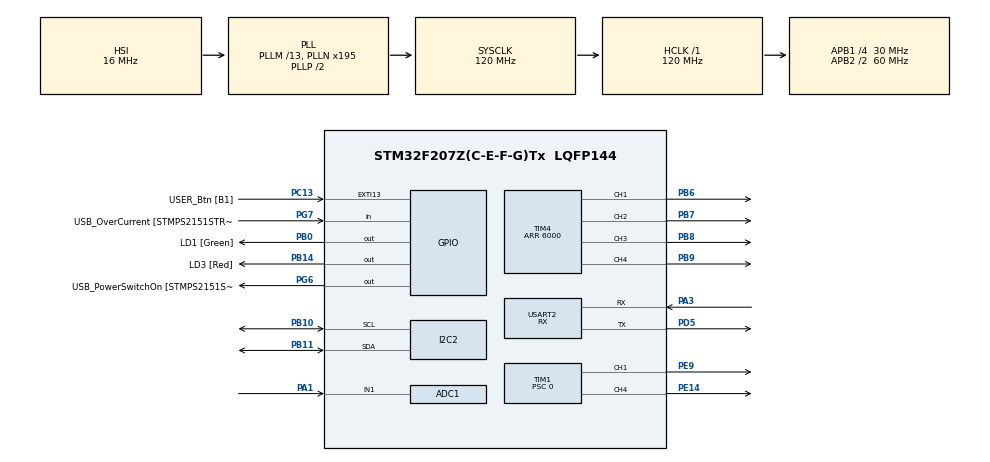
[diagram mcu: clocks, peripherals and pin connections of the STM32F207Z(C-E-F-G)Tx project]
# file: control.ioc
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ADC1.Channel-2\#ChannelRegularConversion=ADC_CHANNEL_1
ADC1.NbrOfConversionFlag=1
ADC1.Rank-2\#ChannelRegularConversion=1
ADC1.SamplingTime-2\#ChannelRegularConversion=ADC_SAMPLETIME_3CYCLES
ADC1.master=1
Dma.Request0=TIM1_CH1
Dma.Request1=TIM1_CH4/TRIG/COM
Dma.TIM1_CH1.0.Direction=DMA_MEMORY_TO_PERIPH
Dma.TIM1_CH1.0.FIFOMode=DMA_FIFOMODE_DISABLE
Dma.TIM1_CH1.0.Instance=DMA2_Stream1
Dma.TIM1_CH1.0.MemDataAlignment=DMA_MDATAALIGN_HALFWORD
Dma.TIM1_CH1.0.MemInc=DMA_MINC_ENABLE
Dma.TIM1_CH1.0.Mode=DMA_CIRCULAR
Dma.TIM1_CH1.0.PeriphDataAlignment=DMA_PDATAALIGN_HALFWORD
Dma.TIM1_CH1.0.PeriphInc=DMA_PINC_DISABLE
Dma.TIM1_CH1.0.Priority=DMA_PRIORITY_HIGH
Dma.TIM1_CH4/TRIG/COM.1.Direction=DMA_MEMORY_TO_PERIPH
Dma.TIM1_CH4/TRIG/COM.1.FIFOMode=DMA_FIFOMODE_DISABLE
Dma.TIM1_CH4/TRIG/COM.1.Instance=DMA2_Stream4
Dma.TIM1_CH4/TRIG/COM.1.MemDataAlignment=DMA_MDATAALIGN_HALFWORD
Dma.TIM1_CH4/TRIG/COM.1.MemInc=DMA_MINC_ENABLE
Dma.TIM1_CH4/TRIG/COM.1.Mode=DMA_CIRCULAR
Dma.TIM1_CH4/TRIG/COM.1.PeriphDataAlignment=DMA_PDATAALIGN_HALFWORD
Dma.TIM1_CH4/TRIG/COM.1.PeriphInc=DMA_PINC_DISABLE
Dma.TIM1_CH4/TRIG/COM.1.Priority=DMA_PRIORITY_HIGH
I2C2.DualAddressMode=I2C_DUALADDRESS_DISABLE
I2C2.I2C_Mode=I2C_Standard
I2C2.OwnAddress=0x53
Mcu.Family=STM32F2
Mcu.Name=STM32F207Z(C-E-F-G)Tx
Mcu.Package=LQFP144
NVIC.DMA2_Stream1_IRQn=true\:0\:0\:false\:false\:true\:false\:true\:true
NVIC.DMA2_Stream4_IRQn=true\:0\:0\:false\:false\:true\:false\:true\:true
NVIC.I2C2_EV_IRQn=true\:0\:0\:false\:false\:true\:true\:true\:true
NVIC.PriorityGroup=NVIC_PRIORITYGROUP_4
NVIC.USART2_IRQn=true\:0\:0\:false\:false\:true\:true\:true\:true
PA1.Signal=ADCx_IN1
PA10.GPIO_Label=USB_ID
PA10.Signal=USB_OTG_FS_ID
PA12.GPIO_Label=USB_DP
PA12.Signal=USB_OTG_FS_DP
PA13.GPIO_Label=TMS
PA13.Mode=Serial_Wire
PA13.Signal=SYS_JTMS-SWDIO
PA14.GPIO_Label=TCK
PA14.Mode=Serial_Wire
PA14.Signal=SYS_JTCK-SWCLK
PA2.GPIO_Label=RMII_MDIO [LAN8742A-CZ-TR_MDIO]
PA2.Signal=ETH_MDIO
PA3.Mode=Asynchronous
PA3.Signal=USART2_RX
PA7.GPIO_Label=RMII_CRS_DV [LAN8742A-CZ-TR_CRS_DV]
PA7.Signal=ETH_CRS_DV
PA9.GPIO_Label=USB_VBUS
PA9.Signal=USB_OTG_FS_VBUS
PB0.GPIO_Label=LD1 [Green]
PB0.Signal=GPIO_Output
PB10.Mode=I2C
PB10.Signal=I2C2_SCL
PB11.Mode=I2C
PB11.Signal=I2C2_SDA
PB13.GPIO_Label=RMII_TXD1 [LAN8742A-CZ-TR_TXD1]
PB13.Signal=ETH_TXD1
PB14.GPIO_Label=LD3 [Red]
PB14.Signal=GPIO_Output
PB3.GPIO_Label=SWO
PB3.Signal=SYS_JTDO-SWO
PB6.Signal=S_TIM4_CH1
PB7.Signal=S_TIM4_CH2
PB8.Signal=S_TIM4_CH3
PB9.Signal=S_TIM4_CH4
PC1.GPIO_Label=RMII_MDC [LAN8742A-CZ-TR_MDC]
PC1.Signal=ETH_MDC
PC13.GPIO_Label=USER_Btn [B1]
PC13.Signal=GPXTI13
PC14-OSC32_IN.Mode=LSE-External-Oscillator
PC14-OSC32_IN.Signal=RCC_OSC32_IN
PC15-OSC32_OUT.Mode=LSE-External-Oscillator
PC15-OSC32_OUT.Signal=RCC_OSC32_OUT
PC4.GPIO_Label=RMII_RXD0 [LAN8742A-CZ-TR_RXD0]
PC4.Signal=ETH_RXD0
PC5.GPIO_Label=RMII_RXD1 [LAN8742A-CZ-TR_RXD1]
PC5.Signal=ETH_RXD1
PD5.Mode=Asynchronous
PD5.Signal=USART2_TX
PD8.GPIO_Label=STLK_RX [STM32F103CBT6_PA2]
PD8.Signal=USART3_TX
PD9.GPIO_Label=STLK_TX [STM32F103CBT6_PA3]
PD9.Signal=USART3_RX
PE14.Signal=S_TIM1_CH4
PE9.Signal=S_TIM1_CH1
PG11.GPIO_Label=RMII_TX_EN [LAN8742A-CZ-TR_TXEN]
PG11.Signal=ETH_TX_EN
PG13.GPIO_Label=RMII_TXD0 [LAN8742A-CZ-TR_TXD0]
PG13.Signal=ETH_TXD0
PG6.GPIO_Label=USB_PowerSwitchOn [STMPS2151STR_EN]
PG6.Signal=GPIO_Output
PG7.GPIO_Label=USB_OverCurrent [STMPS2151STR_FAULT]
PG7.Signal=GPIO_Input
PH0-OSC_IN.GPIO_Label=MCO [STM32F103CBT6_PA8]
PH0-OSC_IN.Mode=HSE-External-Clock-Source
PH0-OSC_IN.Signal=RCC_OSC_IN
PH1-OSC_OUT.Mode=HSE-External-Clock-Source
PH1-OSC_OUT.Signal=RCC_OSC_OUT
ProjectManager.HeapSize=0x200
ProjectManager.StackSize=0x400
ProjectManager.TargetToolchain=CMake
RCC.48MHZClocksFreq_Value=48000000
RCC.AHBFreq_Value=120000000
RCC.APB1CLKDivider=RCC_HCLK_DIV4
RCC.APB1Freq_Value=30000000
RCC.APB1TimFreq_Value=60000000
RCC.APB2CLKDivider=RCC_HCLK_DIV2
RCC.APB2Freq_Value=60000000
RCC.APB2TimFreq_Value=120000000
RCC.CortexFreq_Value=120000000
RCC.HCLKFreq_Value=120000000
RCC.HSE_VALUE=8000000
RCC.HSI_VALUE=16000000
RCC.PLLM=13
RCC.PLLMUL=RCC_PLL_MUL9
RCC.PLLN=195
RCC.PLLQ=5
RCC.PRESCALERUSB=RCC_USBCLKSOURCE_PLL_DIV1_5
RCC.SYSCLKFreq_VALUE=120000000
RCC.SYSCLKSource=RCC_SYSCLKSOURCE_PLLCLK
RCC.SYSCLKSourceVirtual=RCC_SYSCLKSOURCE_PLLCLK
RCC.USBFreq_Value=48000000
RCC.VCOOutputFreq_Value=240000000
SH.ADCx_IN1.0=ADC1_IN1,IN1
SH.S_TIM1_CH1.0=TIM1_CH1,PWM Generation1 CH1
SH.S_TIM1_CH4.0=TIM1_CH4,PWM Generation4 CH4
SH.S_TIM4_CH1.0=TIM4_CH1,PWM Generation1 CH1
SH.S_TIM4_CH2.0=TIM4_CH2,PWM Generation2 CH2
SH.S_TIM4_CH3.0=TIM4_CH3,PWM Generation3 CH3
SH.S_TIM4_CH4.0=TIM4_CH4,PWM Generation4 CH4
TIM1.Channel-PWM\ Generation1\ CH1=TIM_CHANNEL_1
TIM1.Channel-PWM\ Generation4\ CH4=TIM_CHANNEL_4
TIM1.CounterMode=TIM_COUNTERMODE_UP
TIM1.Period=199
TIM1.Prescaler=0
TIM1.Pulse-PWM\ Generation1\ CH1=1
TIM1.Pulse-PWM\ Generation4\ CH4=1
TIM4.Channel-PWM\ Generation1\ CH1=TIM_CHANNEL_1
TIM4.Channel-PWM\ Generation2\ CH2=TIM_CHANNEL_2
TIM4.Channel-PWM\ Generation3\ CH3=TIM_CHANNEL_3
TIM4.Channel-PWM\ Generation4\ CH4=TIM_CHANNEL_4
TIM4.Period=6000
USART2.Mode=MODE_RX
USART2.Parity=PARITY_NONE
USART2.StopBits=STOPBITS_1
USART2.VirtualMode=VM_ASYNC
USART2.WordLength=WORDLENGTH_8B
VP_TIM1_VS_ClockSourceINT.Mode=Internal
VP_TIM4_VS_ClockSourceINT.Mode=Internal
board=NUCLEO-F207ZG

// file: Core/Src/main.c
/* USER CODE BEGIN Header */
/**
  ******************************************************************************
  * @file           : main.c
  * @brief          : Main program body
  ******************************************************************************
  * @attention
  *
  * Copyright (c) 2025 STMicroelectronics.
  * All rights reserved.
  *
  * This software is licensed under terms that can be found in the LICENSE file
  * in the root directory of this software component.
  * If no LICENSE file comes with this software, it is provided AS-IS.
  *
  ******************************************************************************
  */
/* USER CODE END Header */
#include "main.h"
#include "adc.h"
#include "dma.h"
#include "i2c.h"
#include "tim.h"
#include "usart.h"
#include "gpio.h"

/* USER CODE BEGIN Includes */
#include "rgb.h"
#include "rx.h"
#include "motor.h"
#include "battery.h"
#include "accel.h"
/* USER CODE END Includes */

void SystemClock_Config(void);

int main(void)
{

  /* MCU Configuration--------------------------------------------------------*/

  /* Reset of all peripherals, Initializes the Flash interface and the Systick. */
  HAL_Init();

  /* Configure the system clock */
  SystemClock_Config();

  /* Initialize all configured peripherals */
  MX_GPIO_Init();
  MX_DMA_Init();
  MX_TIM4_Init();
  MX_USART2_UART_Init();
  MX_TIM1_Init();
  MX_ADC1_Init();
  MX_I2C2_Init();
  /* USER CODE BEGIN 2 */
  rgb_init();
  rx_init();
  accel_init();
  motor_init();

  /* USER CODE END 2 */

  /* Infinite loop */
  while (1)
  {

    /* USER CODE BEGIN 3 */
    accel_read();
    while (accel_get_state() == ACCEL_BUSY);
    rgb_set_color(accel_data->x, accel_data->y, accel_data->z);
  }
  /* USER CODE END 3 */
}

void SystemClock_Config(void)
{
  RCC_OscInitTypeDef RCC_OscInitStruct = {0};
  RCC_ClkInitTypeDef RCC_ClkInitStruct = {0};

  /** Initializes the RCC Oscillators according to the specified parameters
  * in the RCC_OscInitTypeDef structure.
  */
  RCC_OscInitStruct.OscillatorType = RCC_OSCILLATORTYPE_HSI;
  RCC_OscInitStruct.HSIState = RCC_HSI_ON;
  RCC_OscInitStruct.HSICalibrationValue = RCC_HSICALIBRATION_DEFAULT;
  RCC_OscInitStruct.PLL.PLLState = RCC_PLL_ON;
  RCC_OscInitStruct.PLL.PLLSource = RCC_PLLSOURCE_HSI;
  RCC_OscInitStruct.PLL.PLLM = 13;
  RCC_OscInitStruct.PLL.PLLN = 195;
  RCC_OscInitStruct.PLL.PLLP = RCC_PLLP_DIV2;
  RCC_OscInitStruct.PLL.PLLQ = 5;
  if (HAL_RCC_OscConfig(&RCC_OscInitStruct) != HAL_OK)
  {
    Error_Handler();
  }

  /** Initializes the CPU, AHB and APB buses clocks
  */
  RCC_ClkInitStruct.ClockType = RCC_CLOCKTYPE_HCLK|RCC_CLOCKTYPE_SYSCLK
                              |RCC_CLOCKTYPE_PCLK1|RCC_CLOCKTYPE_PCLK2;
  RCC_ClkInitStruct.SYSCLKSource = RCC_SYSCLKSOURCE_PLLCLK;
  RCC_ClkInitStruct.AHBCLKDivider = RCC_SYSCLK_DIV1;
  RCC_ClkInitStruct.APB1CLKDivider = RCC_HCLK_DIV4;
  RCC_ClkInitStruct.APB2CLKDivider = RCC_HCLK_DIV2;

  if (HAL_RCC_ClockConfig(&RCC_ClkInitStruct, FLASH_LATENCY_3) != HAL_OK)
  {
    Error_Handler();
  }
}

void Error_Handler(void)
{
  __disable_irq();
  while (1)
  {
  }
}
